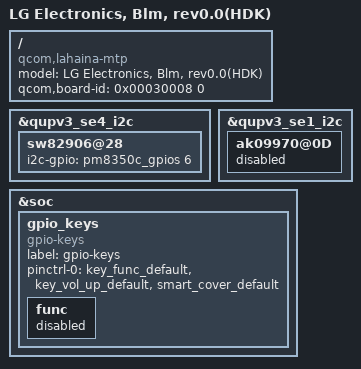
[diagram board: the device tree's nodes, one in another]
/dts-v1/;
/plugin/;

#include "lahaina-blm.dtsi"
#include "lahaina-blm-sound_hdk.dtsi"
#include "../lahaina-blm_camera/lahaina-blm_camera_hdk.dtsi"

/ {
    model = "LG Electronics, Blm, rev0.0(HDK)";
    compatible = "qcom,lahaina-mtp", "qcom,lahaina", "qcom,mtp";
    qcom,board-id = <0x00030008 0>;
};

&qupv3_se4_i2c {
       sw82906@28 {
               i2c-gpio = <&pm8350c_gpios 6 0x00>;
       };
};

&qupv3_se1_i2c {
    ak09970@0D {
        status = "disabled";
    };
};

&soc {
	gpio_keys {
		compatible = "gpio-keys";
		label = "gpio-keys";

		pinctrl-names = "default";
		pinctrl-0 = <&key_func_default &key_vol_up_default &smart_cover_default>;

		func {
			 status = "disabled";
		};
	};
};
